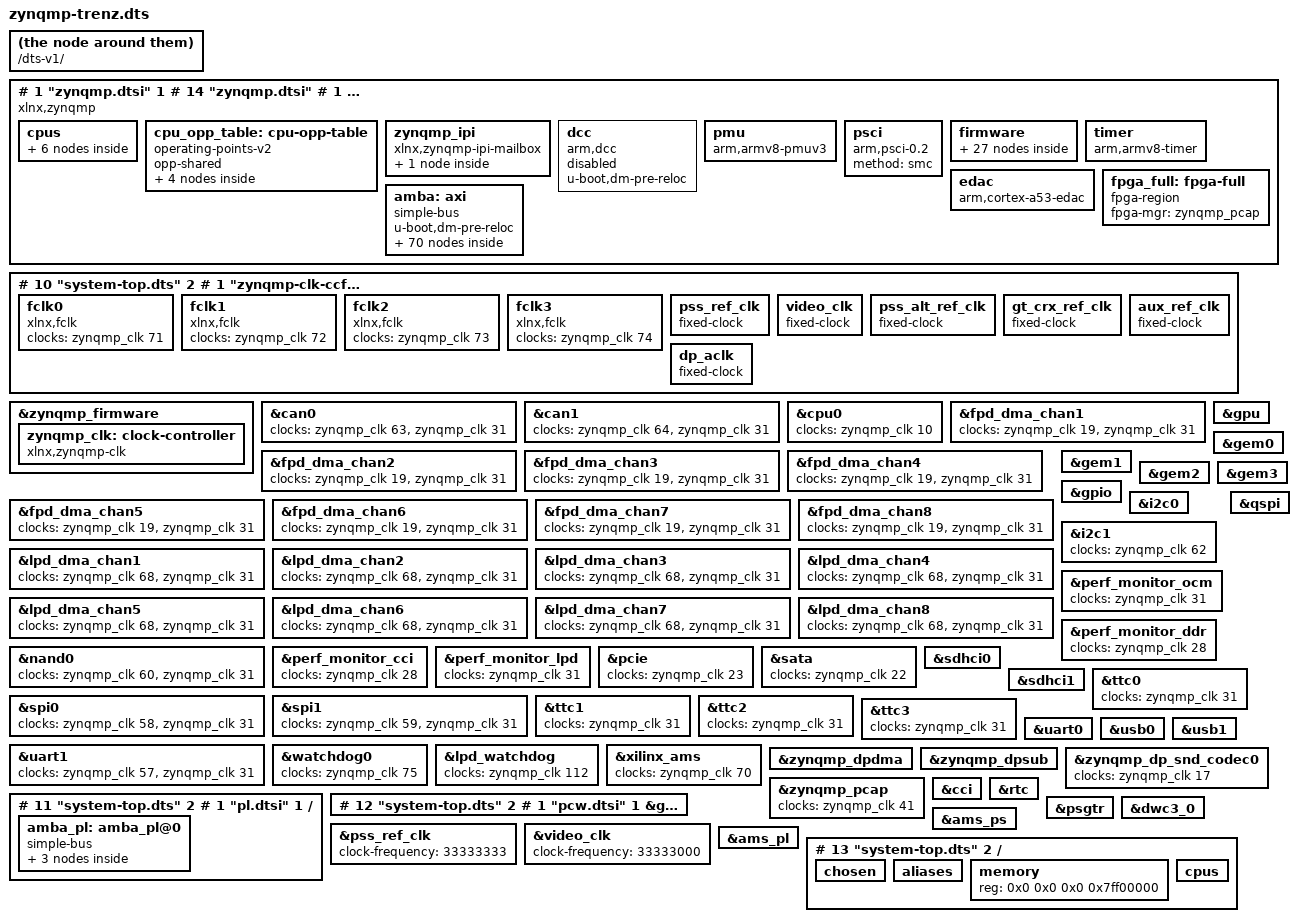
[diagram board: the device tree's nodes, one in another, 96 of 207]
# 1 "system-top.dts"
# 1 "<built-in>"
# 1 "<command-line>"
# 1 "system-top.dts"







/dts-v1/;
# 1 "zynqmp.dtsi" 1
# 14 "zynqmp.dtsi"
# 1 "include/dt-bindings/dma/xlnx-zynqmp-dpdma.h" 1
# 15 "zynqmp.dtsi" 2
# 1 "include/dt-bindings/gpio/gpio.h" 1
# 16 "zynqmp.dtsi" 2
# 1 "include/dt-bindings/power/xlnx-zynqmp-power.h" 1
# 17 "zynqmp.dtsi" 2
# 1 "include/dt-bindings/reset/xlnx-zynqmp-resets.h" 1
# 18 "zynqmp.dtsi" 2

/ {
 compatible = "xlnx,zynqmp";
 #address-cells = <2>;
 #size-cells = <2>;

 cpus {
  #address-cells = <1>;
  #size-cells = <0>;

  cpu0: cpu@0 {
   compatible = "arm,cortex-a53";
   device_type = "cpu";
   enable-method = "psci";
   operating-points-v2 = <&cpu_opp_table>;
   reg = <0x0>;
   cpu-idle-states = <&CPU_SLEEP_0>;
  };

  cpu1: cpu@1 {
   compatible = "arm,cortex-a53";
   device_type = "cpu";
   enable-method = "psci";
   reg = <0x1>;
   operating-points-v2 = <&cpu_opp_table>;
   cpu-idle-states = <&CPU_SLEEP_0>;
  };

  cpu2: cpu@2 {
   compatible = "arm,cortex-a53";
   device_type = "cpu";
   enable-method = "psci";
   reg = <0x2>;
   operating-points-v2 = <&cpu_opp_table>;
   cpu-idle-states = <&CPU_SLEEP_0>;
  };

  cpu3: cpu@3 {
   compatible = "arm,cortex-a53";
   device_type = "cpu";
   enable-method = "psci";
   reg = <0x3>;
   operating-points-v2 = <&cpu_opp_table>;
   cpu-idle-states = <&CPU_SLEEP_0>;
  };

  idle-states {
   entry-method = "psci";

   CPU_SLEEP_0: cpu-sleep-0 {
    compatible = "arm,idle-state";
    arm,psci-suspend-param = <0x40000000>;
    local-timer-stop;
    entry-latency-us = <300>;
    exit-latency-us = <600>;
    min-residency-us = <10000>;
   };
  };
 };

 cpu_opp_table: cpu-opp-table {
  compatible = "operating-points-v2";
  opp-shared;
  opp00 {
   opp-hz = /bits/ 64 <1199999988>;
   opp-microvolt = <1000000>;
   clock-latency-ns = <500000>;
  };
  opp01 {
   opp-hz = /bits/ 64 <599999994>;
   opp-microvolt = <1000000>;
   clock-latency-ns = <500000>;
  };
  opp02 {
   opp-hz = /bits/ 64 <399999996>;
   opp-microvolt = <1000000>;
   clock-latency-ns = <500000>;
  };
  opp03 {
   opp-hz = /bits/ 64 <299999997>;
   opp-microvolt = <1000000>;
   clock-latency-ns = <500000>;
  };
 };

 zynqmp_ipi: zynqmp_ipi {
  u-boot,dm-pre-reloc;
  compatible = "xlnx,zynqmp-ipi-mailbox";
  interrupt-parent = <&gic>;
  interrupts = <0 35 4>;
  xlnx,ipi-id = <0>;
  #address-cells = <2>;
  #size-cells = <2>;
  ranges;

  ipi_mailbox_pmu1: mailbox@ff990400 {
   u-boot,dm-pre-reloc;
   reg = <0x0 0xff9905c0 0x0 0x20>,
         <0x0 0xff9905e0 0x0 0x20>,
         <0x0 0xff990e80 0x0 0x20>,
         <0x0 0xff990ea0 0x0 0x20>;
   reg-names = "local_request_region",
        "local_response_region",
        "remote_request_region",
        "remote_response_region";
   #mbox-cells = <1>;
   xlnx,ipi-id = <4>;
  };
 };

 dcc: dcc {
  compatible = "arm,dcc";
  status = "disabled";
  u-boot,dm-pre-reloc;
 };

 pmu {
  compatible = "arm,armv8-pmuv3";
  interrupt-parent = <&gic>;
  interrupts = <0 143 4>,
        <0 144 4>,
        <0 145 4>,
        <0 146 4>;
 };

 psci {
  compatible = "arm,psci-0.2";
  method = "smc";
 };

 firmware {
  zynqmp_firmware: zynqmp-firmware {
   compatible = "xlnx,zynqmp-firmware";
   u-boot,dm-pre-reloc;
   method = "smc";
   #power-domain-cells = <0x1>;

   zynqmp_power: zynqmp-power {
    u-boot,dm-pre-reloc;
    compatible = "xlnx,zynqmp-power";
    interrupt-parent = <&gic>;
    interrupts = <0 35 4>;
    mboxes = <&ipi_mailbox_pmu1 0>, <&ipi_mailbox_pmu1 1>;
    mbox-names = "tx", "rx";
   };

   nvmem_firmware {
    compatible = "xlnx,zynqmp-nvmem-fw";
    #address-cells = <1>;
    #size-cells = <1>;

    soc_revision: soc_revision@0 {
     reg = <0x0 0x4>;
    };

    efuse_dna: efuse_dna@c {
     reg = <0xc 0xc>;
    };
    efuse_usr0: efuse_usr0@20 {
     reg = <0x20 0x4>;
    };
    efuse_usr1: efuse_usr1@24 {
     reg = <0x24 0x4>;
    };
    efuse_usr2: efuse_usr2@28 {
     reg = <0x28 0x4>;
    };
    efuse_usr3: efuse_usr3@2c {
     reg = <0x2c 0x4>;
    };
    efuse_usr4: efuse_usr4@30 {
     reg = <0x30 0x4>;
    };
    efuse_usr5: efuse_usr5@34 {
     reg = <0x34 0x4>;
    };
    efuse_usr6: efuse_usr6@38 {
     reg = <0x38 0x4>;
    };
    efuse_usr7: efuse_usr7@3c {
     reg = <0x3c 0x4>;
    };
    efuse_miscusr: efuse_miscusr@40 {
     reg = <0x40 0x4>;
    };
    efuse_chash: efuse_chash@50 {
     reg = <0x50 0x4>;
    };
    efuse_pufmisc: efuse_pufmisc@54 {
     reg = <0x54 0x4>;
    };
    efuse_sec: efuse_sec@58 {
     reg = <0x58 0x4>;
    };
    efuse_spkid: efuse_spkid@5c {
     reg = <0x5c 0x4>;
    };
    efuse_ppk0hash: efuse_ppk0hash@a0 {
     reg = <0xa0 0x30>;
    };
    efuse_ppk1hash: efuse_ppk1hash@d0 {
     reg = <0xd0 0x30>;
    };
   };

   zynqmp_pcap: pcap {
    compatible = "xlnx,zynqmp-pcap-fpga";
    clock-names = "ref_clk";
   };

   xlnx_aes: zynqmp-aes {
    compatible = "xlnx,zynqmp-aes";
   };

   zynqmp_reset: reset-controller {
    compatible = "xlnx,zynqmp-reset";
    #reset-cells = <1>;
   };

   pinctrl0: pinctrl {
    compatible = "xlnx,zynqmp-pinctrl";
    status = "disabled";
   };

   xlnx_keccak_384: sha384 {
    compatible = "xlnx,zynqmp-keccak-384";
   };

   xlnx_rsa: zynqmp-rsa {
    compatible = "xlnx,zynqmp-rsa";
   };

   modepin_gpio: gpio {
    compatible = "xlnx,zynqmp-gpio-modepin";
    gpio-controller;
    #gpio-cells = <2>;
   };
  };
 };

 timer {
  compatible = "arm,armv8-timer";
  interrupt-parent = <&gic>;
  interrupts = <1 13 0xf08>,
        <1 14 0xf08>,
        <1 11 0xf08>,
        <1 10 0xf08>;
 };

 edac {
  compatible = "arm,cortex-a53-edac";
 };

 fpga_full: fpga-full {
  compatible = "fpga-region";
  fpga-mgr = <&zynqmp_pcap>;
  #address-cells = <2>;
  #size-cells = <2>;
  ranges;
 };



 amba: axi {
  compatible = "simple-bus";
  u-boot,dm-pre-reloc;
  #address-cells = <2>;
  #size-cells = <2>;
  ranges;

  can0: can@ff060000 {
   compatible = "xlnx,zynq-can-1.0";
   status = "disabled";
   clock-names = "can_clk", "pclk";
   reg = <0x0 0xff060000 0x0 0x1000>;
   interrupts = <0 23 4>;
   interrupt-parent = <&gic>;
   tx-fifo-depth = <0x40>;
   rx-fifo-depth = <0x40>;
   power-domains = <&zynqmp_firmware 47>;
  };

  can1: can@ff070000 {
   compatible = "xlnx,zynq-can-1.0";
   status = "disabled";
   clock-names = "can_clk", "pclk";
   reg = <0x0 0xff070000 0x0 0x1000>;
   interrupts = <0 24 4>;
   interrupt-parent = <&gic>;
   tx-fifo-depth = <0x40>;
   rx-fifo-depth = <0x40>;
   power-domains = <&zynqmp_firmware 48>;
  };

  cci: cci@fd6e0000 {
   compatible = "arm,cci-400";
   status = "disabled";
   reg = <0x0 0xfd6e0000 0x0 0x9000>;
   ranges = <0x0 0x0 0xfd6e0000 0x10000>;
   #address-cells = <1>;
   #size-cells = <1>;

   pmu@9000 {
    compatible = "arm,cci-400-pmu,r1";
    reg = <0x9000 0x5000>;
    interrupt-parent = <&gic>;
    interrupts = <0 123 4>,
          <0 123 4>,
          <0 123 4>,
          <0 123 4>,
          <0 123 4>;
   };
  };


  fpd_dma_chan1: dma-controller@fd500000 {
   status = "disabled";
   compatible = "xlnx,zynqmp-dma-1.0";
   reg = <0x0 0xfd500000 0x0 0x1000>;
   interrupt-parent = <&gic>;
   interrupts = <0 124 4>;
   clock-names = "clk_main", "clk_apb";
   xlnx,bus-width = <128>;
   #stream-id-cells = <1>;
   iommus = <&smmu 0x14e8>;
   power-domains = <&zynqmp_firmware 42>;
   #dma-cells = <1>;
  };

  fpd_dma_chan2: dma-controller@fd510000 {
   status = "disabled";
   compatible = "xlnx,zynqmp-dma-1.0";
   reg = <0x0 0xfd510000 0x0 0x1000>;
   interrupt-parent = <&gic>;
   interrupts = <0 125 4>;
   clock-names = "clk_main", "clk_apb";
   xlnx,bus-width = <128>;
   #stream-id-cells = <1>;
   iommus = <&smmu 0x14e9>;
   power-domains = <&zynqmp_firmware 42>;
   #dma-cells = <1>;
  };

  fpd_dma_chan3: dma-controller@fd520000 {
   status = "disabled";
   compatible = "xlnx,zynqmp-dma-1.0";
   reg = <0x0 0xfd520000 0x0 0x1000>;
   interrupt-parent = <&gic>;
   interrupts = <0 126 4>;
   clock-names = "clk_main", "clk_apb";
   xlnx,bus-width = <128>;
   #stream-id-cells = <1>;
   iommus = <&smmu 0x14ea>;
   power-domains = <&zynqmp_firmware 42>;
   #dma-cells = <1>;
  };

  fpd_dma_chan4: dma-controller@fd530000 {
   status = "disabled";
   compatible = "xlnx,zynqmp-dma-1.0";
   reg = <0x0 0xfd530000 0x0 0x1000>;
   interrupt-parent = <&gic>;
   interrupts = <0 127 4>;
   clock-names = "clk_main", "clk_apb";
   xlnx,bus-width = <128>;
   #stream-id-cells = <1>;
   iommus = <&smmu 0x14eb>;
   power-domains = <&zynqmp_firmware 42>;
   #dma-cells = <1>;
  };

  fpd_dma_chan5: dma-controller@fd540000 {
   status = "disabled";
   compatible = "xlnx,zynqmp-dma-1.0";
   reg = <0x0 0xfd540000 0x0 0x1000>;
   interrupt-parent = <&gic>;
   interrupts = <0 128 4>;
   clock-names = "clk_main", "clk_apb";
   xlnx,bus-width = <128>;
   #stream-id-cells = <1>;
   iommus = <&smmu 0x14ec>;
   power-domains = <&zynqmp_firmware 42>;
   #dma-cells = <1>;
  };

  fpd_dma_chan6: dma-controller@fd550000 {
   status = "disabled";
   compatible = "xlnx,zynqmp-dma-1.0";
   reg = <0x0 0xfd550000 0x0 0x1000>;
   interrupt-parent = <&gic>;
   interrupts = <0 129 4>;
   clock-names = "clk_main", "clk_apb";
   xlnx,bus-width = <128>;
   #stream-id-cells = <1>;
   iommus = <&smmu 0x14ed>;
   power-domains = <&zynqmp_firmware 42>;
   #dma-cells = <1>;
  };

  fpd_dma_chan7: dma-controller@fd560000 {
   status = "disabled";
   compatible = "xlnx,zynqmp-dma-1.0";
   reg = <0x0 0xfd560000 0x0 0x1000>;
   interrupt-parent = <&gic>;
   interrupts = <0 130 4>;
   clock-names = "clk_main", "clk_apb";
   xlnx,bus-width = <128>;
   #stream-id-cells = <1>;
   iommus = <&smmu 0x14ee>;
   power-domains = <&zynqmp_firmware 42>;
   #dma-cells = <1>;
  };

  fpd_dma_chan8: dma-controller@fd570000 {
   status = "disabled";
   compatible = "xlnx,zynqmp-dma-1.0";
   reg = <0x0 0xfd570000 0x0 0x1000>;
   interrupt-parent = <&gic>;
   interrupts = <0 131 4>;
   clock-names = "clk_main", "clk_apb";
   xlnx,bus-width = <128>;
   #stream-id-cells = <1>;
   iommus = <&smmu 0x14ef>;
   power-domains = <&zynqmp_firmware 42>;
   #dma-cells = <1>;
  };

  gic: interrupt-controller@f9010000 {
   compatible = "arm,gic-400";
   #interrupt-cells = <3>;
   reg = <0x0 0xf9010000 0x0 0x10000>,
         <0x0 0xf9020000 0x0 0x20000>,
         <0x0 0xf9040000 0x0 0x20000>,
         <0x0 0xf9060000 0x0 0x20000>;
   interrupt-controller;
   interrupt-parent = <&gic>;
   interrupts = <1 9 0xf04>;
  };

  gpu: gpu@fd4b0000 {
   status = "disabled";
   compatible = "arm,mali-400", "arm,mali-utgard";
   reg = <0x0 0xfd4b0000 0x0 0x10000>;
   interrupt-parent = <&gic>;
   interrupts = <0 132 4>, <0 132 4>, <0 132 4>, <0 132 4>, <0 132 4>, <0 132 4>;
   interrupt-names = "IRQGP", "IRQGPMMU", "IRQPP0", "IRQPPMMU0", "IRQPP1", "IRQPPMMU1";
   clock-names = "gpu", "gpu_pp0", "gpu_pp1";
   power-domains = <&zynqmp_firmware 58>;
  };





  lpd_dma_chan1: dma-controller@ffa80000 {
   status = "disabled";
   compatible = "xlnx,zynqmp-dma-1.0";
   reg = <0x0 0xffa80000 0x0 0x1000>;
   interrupt-parent = <&gic>;
   interrupts = <0 77 4>;
   clock-names = "clk_main", "clk_apb";
   xlnx,bus-width = <64>;
   #stream-id-cells = <1>;

   power-domains = <&zynqmp_firmware 43>;
   #dma-cells = <1>;
  };

  lpd_dma_chan2: dma-controller@ffa90000 {
   status = "disabled";
   compatible = "xlnx,zynqmp-dma-1.0";
   reg = <0x0 0xffa90000 0x0 0x1000>;
   interrupt-parent = <&gic>;
   interrupts = <0 78 4>;
   clock-names = "clk_main", "clk_apb";
   xlnx,bus-width = <64>;
   #stream-id-cells = <1>;

   power-domains = <&zynqmp_firmware 43>;
   #dma-cells = <1>;
  };

  lpd_dma_chan3: dma-controller@ffaa0000 {
   status = "disabled";
   compatible = "xlnx,zynqmp-dma-1.0";
   reg = <0x0 0xffaa0000 0x0 0x1000>;
   interrupt-parent = <&gic>;
   interrupts = <0 79 4>;
   clock-names = "clk_main", "clk_apb";
   xlnx,bus-width = <64>;
   #stream-id-cells = <1>;

   power-domains = <&zynqmp_firmware 43>;
   #dma-cells = <1>;
  };

  lpd_dma_chan4: dma-controller@ffab0000 {
   status = "disabled";
   compatible = "xlnx,zynqmp-dma-1.0";
   reg = <0x0 0xffab0000 0x0 0x1000>;
   interrupt-parent = <&gic>;
   interrupts = <0 80 4>;
   clock-names = "clk_main", "clk_apb";
   xlnx,bus-width = <64>;
   #stream-id-cells = <1>;

   power-domains = <&zynqmp_firmware 43>;
   #dma-cells = <1>;
  };

  lpd_dma_chan5: dma-controller@ffac0000 {
   status = "disabled";
   compatible = "xlnx,zynqmp-dma-1.0";
   reg = <0x0 0xffac0000 0x0 0x1000>;
   interrupt-parent = <&gic>;
   interrupts = <0 81 4>;
   clock-names = "clk_main", "clk_apb";
   xlnx,bus-width = <64>;
   #stream-id-cells = <1>;

   power-domains = <&zynqmp_firmware 43>;
   #dma-cells = <1>;
  };

  lpd_dma_chan6: dma-controller@ffad0000 {
   status = "disabled";
   compatible = "xlnx,zynqmp-dma-1.0";
   reg = <0x0 0xffad0000 0x0 0x1000>;
   interrupt-parent = <&gic>;
   interrupts = <0 82 4>;
   clock-names = "clk_main", "clk_apb";
   xlnx,bus-width = <64>;
   #stream-id-cells = <1>;

   power-domains = <&zynqmp_firmware 43>;
   #dma-cells = <1>;
  };

  lpd_dma_chan7: dma-controller@ffae0000 {
   status = "disabled";
   compatible = "xlnx,zynqmp-dma-1.0";
   reg = <0x0 0xffae0000 0x0 0x1000>;
   interrupt-parent = <&gic>;
   interrupts = <0 83 4>;
   clock-names = "clk_main", "clk_apb";
   xlnx,bus-width = <64>;
   #stream-id-cells = <1>;

   power-domains = <&zynqmp_firmware 43>;
   #dma-cells = <1>;
  };

  lpd_dma_chan8: dma-controller@ffaf0000 {
   status = "disabled";
   compatible = "xlnx,zynqmp-dma-1.0";
   reg = <0x0 0xffaf0000 0x0 0x1000>;
   interrupt-parent = <&gic>;
   interrupts = <0 84 4>;
   clock-names = "clk_main", "clk_apb";
   xlnx,bus-width = <64>;
   #stream-id-cells = <1>;

   power-domains = <&zynqmp_firmware 43>;
   #dma-cells = <1>;
  };

  mc: memory-controller@fd070000 {
   compatible = "xlnx,zynqmp-ddrc-2.40a";
   reg = <0x0 0xfd070000 0x0 0x30000>;
   interrupt-parent = <&gic>;
   interrupts = <0 112 4>;
  };

  nand0: nand-controller@ff100000 {
   compatible = "xlnx,zynqmp-nand-controller", "arasan,nfc-v3p10";
   status = "disabled";
   reg = <0x0 0xff100000 0x0 0x1000>;
   clock-names = "controller", "bus";
   interrupt-parent = <&gic>;
   interrupts = <0 14 4>;
   #address-cells = <1>;
   #size-cells = <0>;
   #stream-id-cells = <1>;
   iommus = <&smmu 0x872>;
   power-domains = <&zynqmp_firmware 44>;
  };

  gem0: ethernet@ff0b0000 {
   compatible = "cdns,zynqmp-gem", "cdns,gem";
   status = "disabled";
   interrupt-parent = <&gic>;
   interrupts = <0 57 4>, <0 57 4>;
   reg = <0x0 0xff0b0000 0x0 0x1000>;
   clock-names = "pclk", "hclk", "tx_clk", "rx_clk", "tsu_clk";
   #address-cells = <1>;
   #size-cells = <0>;
   #stream-id-cells = <1>;
   iommus = <&smmu 0x874>;
   power-domains = <&zynqmp_firmware 29>;
   resets = <&zynqmp_reset 29>;
  };

  gem1: ethernet@ff0c0000 {
   compatible = "cdns,zynqmp-gem", "cdns,gem";
   status = "disabled";
   interrupt-parent = <&gic>;
   interrupts = <0 59 4>, <0 59 4>;
   reg = <0x0 0xff0c0000 0x0 0x1000>;
   clock-names = "pclk", "hclk", "tx_clk", "rx_clk", "tsu_clk";
   #address-cells = <1>;
   #size-cells = <0>;
   #stream-id-cells = <1>;
   iommus = <&smmu 0x875>;
   power-domains = <&zynqmp_firmware 30>;
   resets = <&zynqmp_reset 30>;
  };

  gem2: ethernet@ff0d0000 {
   compatible = "cdns,zynqmp-gem", "cdns,gem";
   status = "disabled";
   interrupt-parent = <&gic>;
   interrupts = <0 61 4>, <0 61 4>;
   reg = <0x0 0xff0d0000 0x0 0x1000>;
   clock-names = "pclk", "hclk", "tx_clk", "rx_clk", "tsu_clk";
   #address-cells = <1>;
   #size-cells = <0>;
   #stream-id-cells = <1>;
   iommus = <&smmu 0x876>;
   power-domains = <&zynqmp_firmware 31>;
   resets = <&zynqmp_reset 31>;
  };

  gem3: ethernet@ff0e0000 {
   compatible = "cdns,zynqmp-gem", "cdns,gem";
   status = "disabled";
   interrupt-parent = <&gic>;
   interrupts = <0 63 4>, <0 63 4>;
   reg = <0x0 0xff0e0000 0x0 0x1000>;
   clock-names = "pclk", "hclk", "tx_clk", "rx_clk", "tsu_clk";
   #address-cells = <1>;
   #size-cells = <0>;
   #stream-id-cells = <1>;
   iommus = <&smmu 0x877>;
   power-domains = <&zynqmp_firmware 32>;
   resets = <&zynqmp_reset 32>;
  };

  gpio: gpio@ff0a0000 {
   compatible = "xlnx,zynqmp-gpio-1.0";
   status = "disabled";
   #gpio-cells = <0x2>;
   gpio-controller;
   interrupt-parent = <&gic>;
   interrupts = <0 16 4>;
   interrupt-controller;
   #interrupt-cells = <2>;
   reg = <0x0 0xff0a0000 0x0 0x1000>;
   power-domains = <&zynqmp_firmware 46>;
  };

  i2c0: i2c@ff020000 {
   compatible = "cdns,i2c-r1p14";
   status = "disabled";
   interrupt-parent = <&gic>;
   interrupts = <0 17 4>;
   reg = <0x0 0xff020000 0x0 0x1000>;
   #address-cells = <1>;
   #size-cells = <0>;
   power-domains = <&zynqmp_firmware 37>;
  };

  i2c1: i2c@ff030000 {
   compatible = "cdns,i2c-r1p14";
   status = "disabled";
   interrupt-parent = <&gic>;
   interrupts = <0 18 4>;
   reg = <0x0 0xff030000 0x0 0x1000>;
   #address-cells = <1>;
   #size-cells = <0>;
   power-domains = <&zynqmp_firmware 38>;
  };

  ocm: memory-controller@ff960000 {
   compatible = "xlnx,zynqmp-ocmc-1.0";
   reg = <0x0 0xff960000 0x0 0x1000>;
   interrupt-parent = <&gic>;
   interrupts = <0 10 4>;
  };

  perf_monitor_ocm: perf-monitor@ffa00000 {
   compatible = "xlnx,axi-perf-monitor";
   reg = <0x0 0xffa00000 0x0 0x10000>;
   interrupts = <0 25 4>;
   interrupt-parent = <&gic>;
   xlnx,enable-profile = <0>;
   xlnx,enable-trace = <0>;
   xlnx,num-monitor-slots = <1>;
   xlnx,enable-event-count = <1>;
   xlnx,enable-event-log = <1>;
   xlnx,have-sampled-metric-cnt = <1>;
   xlnx,num-of-counters = <8>;
   xlnx,metric-count-width = <32>;
   xlnx,metrics-sample-count-width = <32>;
   xlnx,global-count-width = <32>;
   xlnx,metric-count-scale = <1>;
  };

  perf_monitor_ddr: perf-monitor@fd0b0000 {
   compatible = "xlnx,axi-perf-monitor";
   reg = <0x0 0xfd0b0000 0x0 0x10000>;
   interrupts = <0 123 4>;
   interrupt-parent = <&gic>;
   xlnx,enable-profile = <0>;
   xlnx,enable-trace = <0>;
   xlnx,num-monitor-slots = <6>;
   xlnx,enable-event-count = <1>;
   xlnx,enable-event-log = <0>;
   xlnx,have-sampled-metric-cnt = <1>;
   xlnx,num-of-counters = <10>;
   xlnx,metric-count-width = <32>;
   xlnx,metrics-sample-count-width = <32>;
   xlnx,global-count-width = <32>;
   xlnx,metric-count-scale = <1>;
  };

  perf_monitor_cci: perf-monitor@fd490000 {
   compatible = "xlnx,axi-perf-monitor";
   reg = <0x0 0xfd490000 0x0 0x10000>;
   interrupts = <0 123 4>;
   interrupt-parent = <&gic>;
   xlnx,enable-profile = <0>;
   xlnx,enable-trace = <0>;
   xlnx,num-monitor-slots = <1>;
   xlnx,enable-event-count = <1>;
   xlnx,enable-event-log = <0>;
   xlnx,have-sampled-metric-cnt = <1>;
   xlnx,num-of-counters = <8>;
   xlnx,metric-count-width = <32>;
   xlnx,metrics-sample-count-width = <32>;
   xlnx,global-count-width = <32>;
   xlnx,metric-count-scale = <1>;
  };

  perf_monitor_lpd: perf-monitor@ffa10000 {
   compatible = "xlnx,axi-perf-monitor";
   reg = <0x0 0xffa10000 0x0 0x10000>;
   interrupts = <0 25 4>;
   interrupt-parent = <&gic>;
   xlnx,enable-profile = <0>;
   xlnx,enable-trace = <0>;
   xlnx,num-monitor-slots = <1>;
   xlnx,enable-event-count = <1>;
   xlnx,enable-event-log = <1>;
   xlnx,have-sampled-metric-cnt = <1>;
   xlnx,num-of-counters = <8>;
   xlnx,metric-count-width = <32>;
   xlnx,metrics-sample-count-width = <32>;
   xlnx,global-count-width = <32>;
   xlnx,metric-count-scale = <1>;
  };

  pcie: pcie@fd0e0000 {
   compatible = "xlnx,nwl-pcie-2.11";
   status = "disabled";
   #address-cells = <3>;
   #size-cells = <2>;
   #interrupt-cells = <1>;
   msi-controller;
   device_type = "pci";
   interrupt-parent = <&gic>;
   interrupts = <0 118 4>,
         <0 117 4>,
         <0 116 4>,
         <0 115 4>,
         <0 114 4>;
   interrupt-names = "misc", "dummy", "intx",
       "msi1", "msi0";
   msi-parent = <&pcie>;
   reg = <0x0 0xfd0e0000 0x0 0x1000>,
         <0x0 0xfd480000 0x0 0x1000>,
         <0x80 0x00000000 0x0 0x1000000>;
   reg-names = "breg", "pcireg", "cfg";
   ranges = <0x02000000 0x00000000 0xe0000000 0x00000000 0xe0000000 0x00000000 0x10000000
      0x43000000 0x00000006 0x00000000 0x00000006 0x00000000 0x00000002 0x00000000>;
   interrupt-map-mask = <0x0 0x0 0x0 0x7>;
   bus-range = <0x00 0xff>;
   interrupt-map = <0x0 0x0 0x0 0x1 &pcie_intc 0x1>,
     <0x0 0x0 0x0 0x2 &pcie_intc 0x2>,
     <0x0 0x0 0x0 0x3 &pcie_intc 0x3>,
     <0x0 0x0 0x0 0x4 &pcie_intc 0x4>;
   #stream-id-cells = <1>;
   iommus = <&smmu 0x4d0>;
   power-domains = <&zynqmp_firmware 59>;
   pcie_intc: legacy-interrupt-controller {
    interrupt-controller;
    #address-cells = <0>;
    #interrupt-cells = <1>;
   };
  };

  qspi: spi@ff0f0000 {
   u-boot,dm-pre-reloc;
   compatible = "xlnx,zynqmp-qspi-1.0";
   status = "disabled";
   clock-names = "ref_clk", "pclk";
   interrupts = <0 15 4>;
   interrupt-parent = <&gic>;
   num-cs = <1>;
   reg = <0x0 0xff0f0000 0x0 0x1000>,
         <0x0 0xc0000000 0x0 0x8000000>;
   #address-cells = <1>;
   #size-cells = <0>;
   #stream-id-cells = <1>;
   iommus = <&smmu 0x873>;
   power-domains = <&zynqmp_firmware 45>;
  };

  psgtr: phy@fd400000 {
   compatible = "xlnx,zynqmp-psgtr-v1.1";
   status = "disabled";
   reg = <0x0 0xfd400000 0x0 0x40000>,
         <0x0 0xfd3d0000 0x0 0x1000>;
   reg-names = "serdes", "siou";
   #phy-cells = <4>;
  };

  rtc: rtc@ffa60000 {
   compatible = "xlnx,zynqmp-rtc";
   status = "disabled";
   reg = <0x0 0xffa60000 0x0 0x100>;
   interrupt-parent = <&gic>;
   interrupts = <0 26 4>, <0 27 4>;
   interrupt-names = "alarm", "sec";
   calibration = <0x7FFF>;
  };

  sata: ahci@fd0c0000 {
   compatible = "ceva,ahci-1v84";
   status = "disabled";
   reg = <0x0 0xfd0c0000 0x0 0x2000>;
   interrupt-parent = <&gic>;
   interrupts = <0 133 4>;
   power-domains = <&zynqmp_firmware 28>;
   resets = <&zynqmp_reset 16>;
   #stream-id-cells = <4>;


  };

  sdhci0: mmc@ff160000 {
   u-boot,dm-pre-reloc;
   compatible = "xlnx,zynqmp-8.9a", "arasan,sdhci-8.9a";
   status = "disabled";
   interrupt-parent = <&gic>;
   interrupts = <0 48 4>;
   reg = <0x0 0xff160000 0x0 0x1000>;
   clock-names = "clk_xin", "clk_ahb";
   xlnx,device_id = <0>;
   #stream-id-cells = <1>;
   iommus = <&smmu 0x870>;
   power-domains = <&zynqmp_firmware 39>;
   #clock-cells = <1>;
   clock-output-names = "clk_out_sd0", "clk_in_sd0";
   resets = <&zynqmp_reset 38>;
  };

  sdhci1: mmc@ff170000 {
   u-boot,dm-pre-reloc;
   compatible = "xlnx,zynqmp-8.9a", "arasan,sdhci-8.9a";
   status = "disabled";
   interrupt-parent = <&gic>;
   interrupts = <0 49 4>;
   reg = <0x0 0xff170000 0x0 0x1000>;
   clock-names = "clk_xin", "clk_ahb";
   xlnx,device_id = <1>;
   #stream-id-cells = <1>;
   iommus = <&smmu 0x871>;
   power-domains = <&zynqmp_firmware 40>;
   #clock-cells = <1>;
   clock-output-names = "clk_out_sd1", "clk_in_sd1";
   resets = <&zynqmp_reset 39>;
  };

  smmu: smmu@fd800000 {
   compatible = "arm,mmu-500";
   reg = <0x0 0xfd800000 0x0 0x20000>;
   #iommu-cells = <1>;
   status = "disabled";
   #global-interrupts = <1>;
   interrupt-parent = <&gic>;
   interrupts = <0 155 4>,
    <0 155 4>, <0 155 4>, <0 155 4>, <0 155 4>,
    <0 155 4>, <0 155 4>, <0 155 4>, <0 155 4>,
    <0 155 4>, <0 155 4>, <0 155 4>, <0 155 4>,
    <0 155 4>, <0 155 4>, <0 155 4>, <0 155 4>;
  };

  spi0: spi@ff040000 {
   compatible = "cdns,spi-r1p6";
   status = "disabled";
   interrupt-parent = <&gic>;
   interrupts = <0 19 4>;
   reg = <0x0 0xff040000 0x0 0x1000>;
   clock-names = "ref_clk", "pclk";
   #address-cells = <1>;
   #size-cells = <0>;
   power-domains = <&zynqmp_firmware 35>;
  };

  spi1: spi@ff050000 {
   compatible = "cdns,spi-r1p6";
   status = "disabled";
   interrupt-parent = <&gic>;
   interrupts = <0 20 4>;
   reg = <0x0 0xff050000 0x0 0x1000>;
   clock-names = "ref_clk", "pclk";
   #address-cells = <1>;
   #size-cells = <0>;
   power-domains = <&zynqmp_firmware 36>;
  };

  ttc0: timer@ff110000 {
   compatible = "cdns,ttc";
   status = "disabled";
   interrupt-parent = <&gic>;
   interrupts = <0 36 4>, <0 37 4>, <0 38 4>;
   reg = <0x0 0xff110000 0x0 0x1000>;
   timer-width = <32>;
   power-domains = <&zynqmp_firmware 24>;
  };

  ttc1: timer@ff120000 {
   compatible = "cdns,ttc";
   status = "disabled";
   interrupt-parent = <&gic>;
   interrupts = <0 39 4>, <0 40 4>, <0 41 4>;
   reg = <0x0 0xff120000 0x0 0x1000>;
   timer-width = <32>;
   power-domains = <&zynqmp_firmware 25>;
  };

  ttc2: timer@ff130000 {
   compatible = "cdns,ttc";
   status = "disabled";
   interrupt-parent = <&gic>;
   interrupts = <0 42 4>, <0 43 4>, <0 44 4>;
   reg = <0x0 0xff130000 0x0 0x1000>;
   timer-width = <32>;
   power-domains = <&zynqmp_firmware 26>;
  };

  ttc3: timer@ff140000 {
   compatible = "cdns,ttc";
   status = "disabled";
   interrupt-parent = <&gic>;
   interrupts = <0 45 4>, <0 46 4>, <0 47 4>;
   reg = <0x0 0xff140000 0x0 0x1000>;
   timer-width = <32>;
   power-domains = <&zynqmp_firmware 27>;
  };

  uart0: serial@ff000000 {
   u-boot,dm-pre-reloc;
   compatible = "xlnx,zynqmp-uart", "cdns,uart-r1p12";
   status = "disabled";
   interrupt-parent = <&gic>;
   interrupts = <0 21 4>;
   reg = <0x0 0xff000000 0x0 0x1000>;
   clock-names = "uart_clk", "pclk";
   power-domains = <&zynqmp_firmware 33>;
  };

  uart1: serial@ff010000 {
   u-boot,dm-pre-reloc;
   compatible = "xlnx,zynqmp-uart", "cdns,uart-r1p12";
   status = "disabled";
   interrupt-parent = <&gic>;
   interrupts = <0 22 4>;
   reg = <0x0 0xff010000 0x0 0x1000>;
   clock-names = "uart_clk", "pclk";
   power-domains = <&zynqmp_firmware 34>;
  };

  usb0: usb0@ff9d0000 {
   #address-cells = <2>;
   #size-cells = <2>;
   status = "disabled";
   compatible = "xlnx,zynqmp-dwc3";
   reg = <0x0 0xff9d0000 0x0 0x100>;
   clock-names = "bus_clk", "ref_clk";
   power-domains = <&zynqmp_firmware 22>;
   resets = <&zynqmp_reset 59>,
     <&zynqmp_reset 61>,
     <&zynqmp_reset 63>;
   reset-names = "usb_crst", "usb_hibrst", "usb_apbrst";
   reset-gpios = <&modepin_gpio 1 1>;
   ranges;

   dwc3_0: usb@fe200000 {
    compatible = "snps,dwc3";
    status = "disabled";
    reg = <0x0 0xfe200000 0x0 0x40000>;
    interrupt-parent = <&gic>;
    interrupt-names = "dwc_usb3", "otg", "hiber";
    interrupts = <0 65 4>, <0 69 4>, <0 75 4>;
    #stream-id-cells = <1>;
    iommus = <&smmu 0x860>;
    snps,quirk-frame-length-adjustment = <0x20>;
    snps,refclk_fladj;
    snps,enable_guctl1_resume_quirk;
    snps,enable_guctl1_ipd_quirk;
    snps,xhci-stream-quirk;

   };
  };

  usb1: usb1@ff9e0000 {
   #address-cells = <2>;
   #size-cells = <2>;
   status = "disabled";
   compatible = "xlnx,zynqmp-dwc3";
   reg = <0x0 0xff9e0000 0x0 0x100>;
   clock-names = "bus_clk", "ref_clk";
   power-domains = <&zynqmp_firmware 23>;
   resets = <&zynqmp_reset 60>,
     <&zynqmp_reset 62>,
     <&zynqmp_reset 64>;
   reset-names = "usb_crst", "usb_hibrst", "usb_apbrst";

   ranges;

   dwc3_1: usb@fe300000 {
    compatible = "snps,dwc3";
    status = "disabled";
    reg = <0x0 0xfe300000 0x0 0x40000>;
    interrupt-parent = <&gic>;
    interrupt-names = "dwc_usb3", "otg", "hiber";
    interrupts = <0 70 4>, <0 74 4>, <0 76 4>;
    #stream-id-cells = <1>;
    iommus = <&smmu 0x861>;
    snps,quirk-frame-length-adjustment = <0x20>;
    snps,refclk_fladj;
    snps,enable_guctl1_resume_quirk;
    snps,enable_guctl1_ipd_quirk;
    snps,xhci-stream-quirk;
   };
  };

  watchdog0: watchdog@fd4d0000 {
   compatible = "cdns,wdt-r1p2";
   status = "disabled";
   interrupt-parent = <&gic>;
   interrupts = <0 113 1>;
   reg = <0x0 0xfd4d0000 0x0 0x1000>;
   timeout-sec = <60>;
   reset-on-timeout;
  };

  lpd_watchdog: watchdog@ff150000 {
   compatible = "cdns,wdt-r1p2";
   status = "disabled";
   interrupt-parent = <&gic>;
   interrupts = <0 52 1>;
   reg = <0x0 0xff150000 0x0 0x1000>;
   timeout-sec = <10>;
  };

  xilinx_ams: ams@ffa50000 {
   compatible = "xlnx,zynqmp-ams";
   status = "disabled";
   interrupt-parent = <&gic>;
   interrupts = <0 56 4>;
   interrupt-names = "ams-irq";
   reg = <0x0 0xffa50000 0x0 0x800>;
   reg-names = "ams-base";
   #address-cells = <2>;
   #size-cells = <2>;
   #io-channel-cells = <1>;
   ranges;

   ams_ps: ams_ps@ffa50800 {
    compatible = "xlnx,zynqmp-ams-ps";
    status = "disabled";
    reg = <0x0 0xffa50800 0x0 0x400>;
   };

   ams_pl: ams_pl@ffa50c00 {
    compatible = "xlnx,zynqmp-ams-pl";
    status = "disabled";
    reg = <0x0 0xffa50c00 0x0 0x400>;
   };
  };

  zynqmp_dpdma: dma-controller@fd4c0000 {
   compatible = "xlnx,zynqmp-dpdma";
   status = "disabled";
   reg = <0x0 0xfd4c0000 0x0 0x1000>;
   interrupts = <0 122 4>;
   interrupt-parent = <&gic>;
   clock-names = "axi_clk";
   power-domains = <&zynqmp_firmware 41>;
   dma-channels = <6>;
   #stream-id-cells = <1>;
   iommus = <&smmu 0xce4>;
   #dma-cells = <1>;
  };

  zynqmp_dpaud_setting: dp_aud@fd4ac000 {
   compatible = "xlnx,zynqmp-dpaud-setting", "syscon";
   reg = <0x0 0xfd4ac000 0x0 0x1000>;
  };

  zynqmp_dpsub: display@fd4a0000 {
   u-boot,dm-pre-reloc;
   compatible = "xlnx,zynqmp-dpsub-1.7";
   status = "disabled";
   reg = <0x0 0xfd4a0000 0x0 0x1000>,
         <0x0 0xfd4aa000 0x0 0x1000>,
         <0x0 0xfd4ab000 0x0 0x1000>;
   reg-names = "dp", "blend", "av_buf";
   xlnx,dpaud-reg = <&zynqmp_dpaud_setting>;
   interrupts = <0 119 4>;
   interrupt-parent = <&gic>;
   #stream-id-cells = <1>;
   iommus = <&smmu 0xce3>;
   clock-names = "dp_apb_clk", "dp_aud_clk", "dp_vtc_pixel_clk_in";
   power-domains = <&zynqmp_firmware 41>;
   resets = <&zynqmp_reset 3>;
   dma-names = "vid0", "vid1", "vid2", "gfx0";
   dmas = <&zynqmp_dpdma 0>,
    <&zynqmp_dpdma 1>,
    <&zynqmp_dpdma 2>,
    <&zynqmp_dpdma 3>;


   i2c-bus {
   };

   zynqmp_dp_snd_codec0: zynqmp_dp_snd_codec0 {
    compatible = "xlnx,dp-snd-codec";
    clock-names = "aud_clk";
   };

   zynqmp_dp_snd_pcm0: zynqmp_dp_snd_pcm0 {
    compatible = "xlnx,dp-snd-pcm0";
    dmas = <&zynqmp_dpdma 4>;
    dma-names = "tx";
   };

   zynqmp_dp_snd_pcm1: zynqmp_dp_snd_pcm1 {
    compatible = "xlnx,dp-snd-pcm1";
    dmas = <&zynqmp_dpdma 5>;
    dma-names = "tx";
   };

   zynqmp_dp_snd_card0: zynqmp_dp_snd_card {
    compatible = "xlnx,dp-snd-card";
    xlnx,dp-snd-pcm = <&zynqmp_dp_snd_pcm0>,
        <&zynqmp_dp_snd_pcm1>;
    xlnx,dp-snd-codec = <&zynqmp_dp_snd_codec0>;
   };
  };
 };
};
# 10 "system-top.dts" 2
# 1 "zynqmp-clk-ccf.dtsi" 1
# 9 "zynqmp-clk-ccf.dtsi"
# 1 "include/dt-bindings/clock/xlnx-zynqmp-clk.h" 1
# 10 "zynqmp-clk-ccf.dtsi" 2

/ {
 fclk0: fclk0 {
  status = "okay";
  compatible = "xlnx,fclk";
  clocks = <&zynqmp_clk 71>;
 };

 fclk1: fclk1 {
  status = "okay";
  compatible = "xlnx,fclk";
  clocks = <&zynqmp_clk 72>;
 };

 fclk2: fclk2 {
  status = "okay";
  compatible = "xlnx,fclk";
  clocks = <&zynqmp_clk 73>;
 };

 fclk3: fclk3 {
  status = "okay";
  compatible = "xlnx,fclk";
  clocks = <&zynqmp_clk 74>;
 };

 pss_ref_clk: pss_ref_clk {
  u-boot,dm-pre-reloc;
  compatible = "fixed-clock";
  #clock-cells = <0>;
  clock-frequency = <33333333>;
 };

 video_clk: video_clk {
  u-boot,dm-pre-reloc;
  compatible = "fixed-clock";
  #clock-cells = <0>;
  clock-frequency = <27000000>;
 };

 pss_alt_ref_clk: pss_alt_ref_clk {
  u-boot,dm-pre-reloc;
  compatible = "fixed-clock";
  #clock-cells = <0>;
  clock-frequency = <0>;
 };

 gt_crx_ref_clk: gt_crx_ref_clk {
  u-boot,dm-pre-reloc;
  compatible = "fixed-clock";
  #clock-cells = <0>;
  clock-frequency = <108000000>;
 };

 aux_ref_clk: aux_ref_clk {
  u-boot,dm-pre-reloc;
  compatible = "fixed-clock";
  #clock-cells = <0>;
  clock-frequency = <27000000>;
 };

 dp_aclk: dp_aclk {
  compatible = "fixed-clock";
  #clock-cells = <0>;
  clock-frequency = <100000000>;
  clock-accuracy = <100>;
 };
};

&zynqmp_firmware {
 zynqmp_clk: clock-controller {
  u-boot,dm-pre-reloc;
  #clock-cells = <1>;
  compatible = "xlnx,zynqmp-clk";
  clocks = <&pss_ref_clk>, <&video_clk>, <&pss_alt_ref_clk>,
    <&aux_ref_clk>, <&gt_crx_ref_clk>;
  clock-names = "pss_ref_clk", "video_clk", "pss_alt_ref_clk",
         "aux_ref_clk", "gt_crx_ref_clk";
 };
};

&can0 {
 clocks = <&zynqmp_clk 63>, <&zynqmp_clk 31>;
};

&can1 {
 clocks = <&zynqmp_clk 64>, <&zynqmp_clk 31>;
};

&cpu0 {
 clocks = <&zynqmp_clk 10>;
};

&fpd_dma_chan1 {
 clocks = <&zynqmp_clk 19>, <&zynqmp_clk 31>;
};

&fpd_dma_chan2 {
 clocks = <&zynqmp_clk 19>, <&zynqmp_clk 31>;
};

&fpd_dma_chan3 {
 clocks = <&zynqmp_clk 19>, <&zynqmp_clk 31>;
};

&fpd_dma_chan4 {
 clocks = <&zynqmp_clk 19>, <&zynqmp_clk 31>;
};

&fpd_dma_chan5 {
 clocks = <&zynqmp_clk 19>, <&zynqmp_clk 31>;
};

&fpd_dma_chan6 {
 clocks = <&zynqmp_clk 19>, <&zynqmp_clk 31>;
};

&fpd_dma_chan7 {
 clocks = <&zynqmp_clk 19>, <&zynqmp_clk 31>;
};

&fpd_dma_chan8 {
 clocks = <&zynqmp_clk 19>, <&zynqmp_clk 31>;
};

&gpu {
 clocks = <&zynqmp_clk 24>, <&zynqmp_clk 25>, <&zynqmp_clk 26>;
};

&lpd_dma_chan1 {
 clocks = <&zynqmp_clk 68>, <&zynqmp_clk 31>;
};

&lpd_dma_chan2 {
 clocks = <&zynqmp_clk 68>, <&zynqmp_clk 31>;
};

&lpd_dma_chan3 {
 clocks = <&zynqmp_clk 68>, <&zynqmp_clk 31>;
};

&lpd_dma_chan4 {
 clocks = <&zynqmp_clk 68>, <&zynqmp_clk 31>;
};

&lpd_dma_chan5 {
 clocks = <&zynqmp_clk 68>, <&zynqmp_clk 31>;
};

&lpd_dma_chan6 {
 clocks = <&zynqmp_clk 68>, <&zynqmp_clk 31>;
};

&lpd_dma_chan7 {
 clocks = <&zynqmp_clk 68>, <&zynqmp_clk 31>;
};

&lpd_dma_chan8 {
 clocks = <&zynqmp_clk 68>, <&zynqmp_clk 31>;
};

&nand0 {
 clocks = <&zynqmp_clk 60>, <&zynqmp_clk 31>;
};

&gem0 {
 clocks = <&zynqmp_clk 31>, <&zynqmp_clk 104>, <&zynqmp_clk 45>,
   <&zynqmp_clk 49>, <&zynqmp_clk 44>;
};

&gem1 {
 clocks = <&zynqmp_clk 31>, <&zynqmp_clk 105>, <&zynqmp_clk 46>,
   <&zynqmp_clk 50>, <&zynqmp_clk 44>;
};

&gem2 {
 clocks = <&zynqmp_clk 31>, <&zynqmp_clk 106>, <&zynqmp_clk 47>,
   <&zynqmp_clk 51>, <&zynqmp_clk 44>;
};

&gem3 {
 clocks = <&zynqmp_clk 31>, <&zynqmp_clk 107>, <&zynqmp_clk 48>,
   <&zynqmp_clk 52>, <&zynqmp_clk 44>;
};

&gpio {
 clocks = <&zynqmp_clk 31>;
};

&i2c0 {
 clocks = <&zynqmp_clk 61>;
};

&i2c1 {
 clocks = <&zynqmp_clk 62>;
};

&perf_monitor_ocm {
 clocks = <&zynqmp_clk 31>;
};

&perf_monitor_ddr {
 clocks = <&zynqmp_clk 28>;
};

&perf_monitor_cci {
 clocks = <&zynqmp_clk 28>;
};

&perf_monitor_lpd {
 clocks = <&zynqmp_clk 31>;
};

&pcie {
 clocks = <&zynqmp_clk 23>;
};

&qspi {
 clocks = <&zynqmp_clk 53>, <&zynqmp_clk 31>;
};

&sata {
 clocks = <&zynqmp_clk 22>;
};

&sdhci0 {
 clocks = <&zynqmp_clk 54>, <&zynqmp_clk 31>;
 assigned-clocks = <&zynqmp_clk 54>;
};

&sdhci1 {
 clocks = <&zynqmp_clk 55>, <&zynqmp_clk 31>;
 assigned-clocks = <&zynqmp_clk 55>;
};

&spi0 {
 clocks = <&zynqmp_clk 58>, <&zynqmp_clk 31>;
};

&spi1 {
 clocks = <&zynqmp_clk 59>, <&zynqmp_clk 31>;
};

&ttc0 {
 clocks = <&zynqmp_clk 31>;
};

&ttc1 {
 clocks = <&zynqmp_clk 31>;
};

&ttc2 {
 clocks = <&zynqmp_clk 31>;
};

&ttc3 {
 clocks = <&zynqmp_clk 31>;
};

&uart0 {
 clocks = <&zynqmp_clk 56>, <&zynqmp_clk 31>;
};

&uart1 {
 clocks = <&zynqmp_clk 57>, <&zynqmp_clk 31>;
};

&usb0 {
 clocks = <&zynqmp_clk 32>, <&zynqmp_clk 34>;
 assigned-clocks = <&zynqmp_clk 32>, <&zynqmp_clk 34>;
};

&usb1 {
 clocks = <&zynqmp_clk 33>, <&zynqmp_clk 34>;
 assigned-clocks = <&zynqmp_clk 33>, <&zynqmp_clk 34>;
};

&watchdog0 {
 clocks = <&zynqmp_clk 75>;
};

&lpd_watchdog {
 clocks = <&zynqmp_clk 112>;
};

&xilinx_ams {
 clocks = <&zynqmp_clk 70>;
};

&zynqmp_dpdma {
 clocks = <&zynqmp_clk 20>;
 assigned-clocks = <&zynqmp_clk 20>;
};

&zynqmp_dpsub {
 clocks = <&dp_aclk>, <&zynqmp_clk 17>, <&zynqmp_clk 16>;
 assigned-clocks = <&zynqmp_clk 18>, <&zynqmp_clk 17>, <&zynqmp_clk 16>;
};

&zynqmp_dp_snd_codec0 {
 clocks = <&zynqmp_clk 17>;
};

&zynqmp_pcap {
 clocks = <&zynqmp_clk 41>;
};
# 11 "system-top.dts" 2
# 1 "pl.dtsi" 1







/ {
 amba_pl: amba_pl@0 {
  #address-cells = <2>;
  #size-cells = <2>;
  compatible = "simple-bus";
  ranges ;
  axi_dma_0: dma@80000000 {
   #dma-cells = <1>;
   clock-names = "s_axi_lite_aclk", "m_axi_mm2s_aclk", "m_axi_s2mm_aclk";
   clocks = <&zynqmp_clk 71>, <&zynqmp_clk 71>, <&zynqmp_clk 71>;
   compatible = "xlnx,axi-dma-7.1", "xlnx,axi-dma-1.00.a";
   interrupt-names = "mm2s_introut", "s2mm_introut";
   interrupt-parent = <&gic>;
   interrupts = <0 89 4 0 90 4>;
   reg = <0x0 0x80000000 0x0 0x1000>;
   xlnx,addrwidth = <0x20>;
   xlnx,sg-length-width = <0xe>;
   dma-channel@80000000 {
    compatible = "xlnx,axi-dma-mm2s-channel";
    dma-channels = <0x1>;
    interrupts = <0 89 4>;
    xlnx,datawidth = <0x20>;
    xlnx,device-id = <0x0>;
   };
   dma-channel@80000030 {
    compatible = "xlnx,axi-dma-s2mm-channel";
    dma-channels = <0x1>;
    interrupts = <0 90 4>;
    xlnx,datawidth = <0x20>;
    xlnx,device-id = <0x0>;
   };
  };
 };
};
# 12 "system-top.dts" 2
# 1 "pcw.dtsi" 1







&gic {
 num_cpus = <2>;
 num_interrupts = <96>;
};
&lpd_dma_chan1 {
 status = "okay";
};
&lpd_dma_chan2 {
 status = "okay";
};
&lpd_dma_chan3 {
 status = "okay";
};
&lpd_dma_chan4 {
 status = "okay";
};
&lpd_dma_chan5 {
 status = "okay";
};
&lpd_dma_chan6 {
 status = "okay";
};
&lpd_dma_chan7 {
 status = "okay";
};
&lpd_dma_chan8 {
 status = "okay";
};
&xilinx_ams {
 status = "okay";
};
&cci {
 status = "okay";
};
&gem3 {
 phy-mode = "rgmii-id";
 status = "okay";
 xlnx,ptp-enet-clock = <0x0>;
};
&fpd_dma_chan1 {
 status = "okay";
};
&fpd_dma_chan2 {
 status = "okay";
};
&fpd_dma_chan3 {
 status = "okay";
};
&fpd_dma_chan4 {
 status = "okay";
};
&fpd_dma_chan5 {
 status = "okay";
};
&fpd_dma_chan6 {
 status = "okay";
};
&fpd_dma_chan7 {
 status = "okay";
};
&fpd_dma_chan8 {
 status = "okay";
};
&gpio {
 emio-gpio-width = <32>;
 gpio-mask-high = <0x0>;
 gpio-mask-low = <0x5600>;
 status = "okay";
};
&i2c0 {
 clock-frequency = <400000>;
 status = "okay";
};
&qspi {
 is-dual = <1>;
 num-cs = <1>;
 spi-rx-bus-width = <4>;
 spi-tx-bus-width = <4>;
 status = "okay";
};
&rtc {
 status = "okay";
};
&sdhci0 {
 clock-frequency = <200000000>;
 status = "okay";
 xlnx,mio-bank = <0x0>;
};
&sdhci1 {
 clock-frequency = <200000000>;
 status = "okay";
 xlnx,mio-bank = <0x1>;
};
&psgtr {
 status = "okay";
};
&uart0 {
 cts-override ;
 device_type = "serial";
 port-number = <0>;
 status = "okay";
 u-boot,dm-pre-reloc ;
};
&usb0 {
 status = "okay";
 xlnx,tz-nonsecure = <0x1>;
 xlnx,usb-polarity = <0x0>;
 xlnx,usb-reset-io = <0x19>;
 xlnx,usb-reset-mode = <0x2>;
};
&dwc3_0 {
 /delete-property/ phy-names ;
 /delete-property/ phys ;
 maximum-speed = "high-speed";
 snps,dis_u2_susphy_quirk ;
 snps,dis_u3_susphy_quirk ;
 status = "okay";
};
&lpd_watchdog {
 status = "okay";
};
&watchdog0 {
 status = "okay";
};
&pss_ref_clk {
 clock-frequency = <33333333>;
};
&video_clk {
 clock-frequency = <33333000>;
};
&ams_ps {
 status = "okay";
};
&ams_pl {
 status = "okay";
};
# 13 "system-top.dts" 2
/ {
 chosen {
  bootargs = "earlycon";
  stdout-path = "serial0:115200n8";
 };
 aliases {
  ethernet0 = &gem3;
  i2c0 = &i2c0;
  serial0 = &uart0;
  spi0 = &qspi;
 };
 memory {
  device_type = "memory";
  reg = <0x0 0x0 0x0 0x7ff00000>;
 };
 cpus {
  /delete-node/ cpu@2 ;
  /delete-node/ cpu@3 ;
 };
};
